# nrf9120 register map
Vendor: Nordic Semiconductor; Series: nrf91; File version: 1
CPU: CM33 r0p4, little endian, MPU, FPU, 3 interrupt priority bits, 69 interrupts
Registers are 32-bit, read-write, reset 0x0 unless marked. A register's access mark holds for its fields unless they carry their own. Offsets are from the block's base; [hi:lo] are bit positions; lines under a group give offsets from that group; {n}, {i} and the like mark numbered series; 'fields as' and 'values as' point back to an identical list.

## POWER_NS — Power control 0
Base 0x40005000; alternate view of CLOCK_NS
Same registers: POWER_S 0x50005000 (alternate view of CLOCK_S)
0x70 TASKS_PWMREQSTART wo — Request forcing PWM mode in external DC/DC voltage regulator. (Drives FPWM_DCDC pin high or low depending on a setting in UICR).
  [0] TASKS_PWMREQSTART
    1=Trigger task
0x74 TASKS_PWMREQSTOP wo — Stop requesting forcing PWM mode in external DC/DC voltage regulator
  [0] TASKS_PWMREQSTOP
    1=Trigger task
0x78 TASKS_CONSTLAT wo — Enable constant latency mode.
  [0] TASKS_CONSTLAT
    1=Trigger task
0x7C TASKS_LOWPWR wo — Enable low power mode (variable latency)
  [0] TASKS_LOWPWR
    1=Trigger task
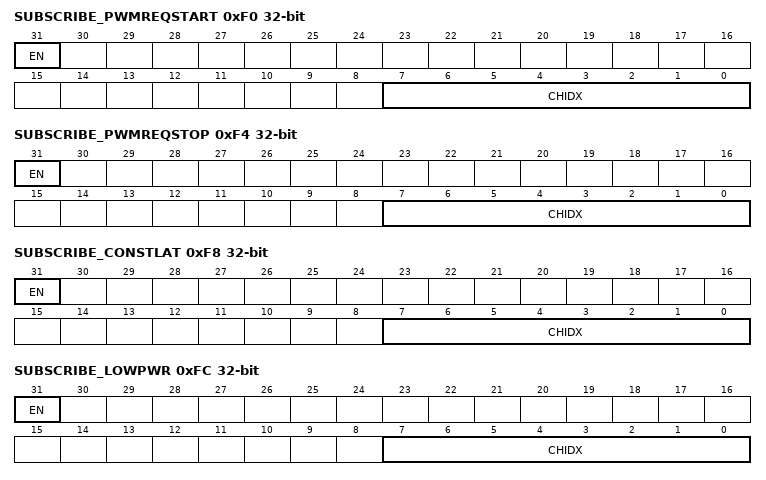
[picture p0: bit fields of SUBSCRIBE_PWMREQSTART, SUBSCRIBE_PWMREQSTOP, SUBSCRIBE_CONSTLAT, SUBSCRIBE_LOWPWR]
0xF0 SUBSCRIBE_PWMREQSTART — Subscribe configuration for task PWMREQSTART
  [31] EN
    0=Disabled (Disable subscription); 1=Enabled (Enable subscription)
  [7:0] CHIDX — DPPI channel that task PWMREQSTART will subscribe to
0xF4 SUBSCRIBE_PWMREQSTOP — Subscribe configuration for task PWMREQSTOP
  [31] EN
    values as SUBSCRIBE_PWMREQSTART.EN
  [7:0] CHIDX — DPPI channel that task PWMREQSTOP will subscribe to
0xF8 SUBSCRIBE_CONSTLAT — Subscribe configuration for task CONSTLAT
  [31] EN
    values as SUBSCRIBE_PWMREQSTART.EN
  [7:0] CHIDX — DPPI channel that task CONSTLAT will subscribe to
0xFC SUBSCRIBE_LOWPWR — Subscribe configuration for task LOWPWR
  [31] EN
    values as SUBSCRIBE_PWMREQSTART.EN
  [7:0] CHIDX — DPPI channel that task LOWPWR will subscribe to
0x108 EVENTS_POFWARN — Power failure warning
  [0] EVENTS_POFWARN
    0=NotGenerated (Event not generated); 1=Generated (Event generated)
0x114 EVENTS_SLEEPENTER — CPU entered WFI/WFE sleep
  [0] EVENTS_SLEEPENTER
    values as EVENTS_POFWARN.EVENTS_POFWARN
0x118 EVENTS_SLEEPEXIT — CPU exited WFI/WFE sleep
  [0] EVENTS_SLEEPEXIT
    values as EVENTS_POFWARN.EVENTS_POFWARN
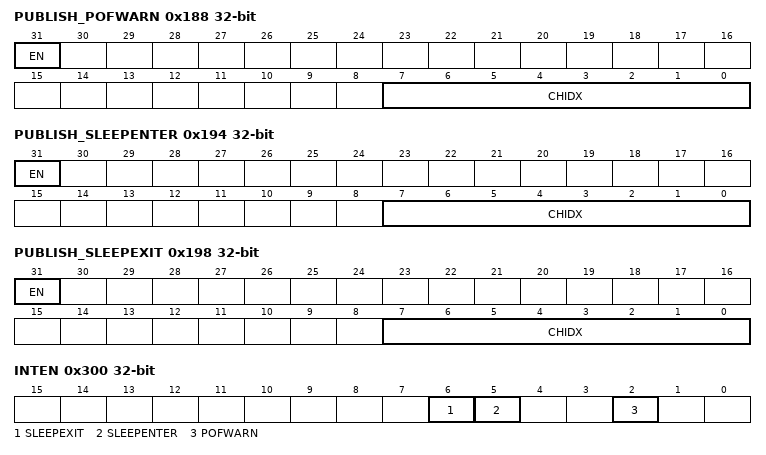
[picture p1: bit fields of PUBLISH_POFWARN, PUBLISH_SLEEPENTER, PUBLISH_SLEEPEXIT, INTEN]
0x188 PUBLISH_POFWARN — Publish configuration for event POFWARN
  [31] EN
    0=Disabled (Disable publishing); 1=Enabled (Enable publishing)
  [7:0] CHIDX — DPPI channel that event POFWARN will publish to
0x194 PUBLISH_SLEEPENTER — Publish configuration for event SLEEPENTER
  [31] EN
    values as PUBLISH_POFWARN.EN
  [7:0] CHIDX — DPPI channel that event SLEEPENTER will publish to
0x198 PUBLISH_SLEEPEXIT — Publish configuration for event SLEEPEXIT
  [31] EN
    values as PUBLISH_POFWARN.EN
  [7:0] CHIDX — DPPI channel that event SLEEPEXIT will publish to
0x300 INTEN — Enable or disable interrupt
  [all] fields
    0=Disabled; 1=Enabled
  [6] SLEEPEXIT — Enable or disable interrupt for event SLEEPEXIT
  [5] SLEEPENTER — Enable or disable interrupt for event SLEEPENTER
  [2] POFWARN — Enable or disable interrupt for event POFWARN
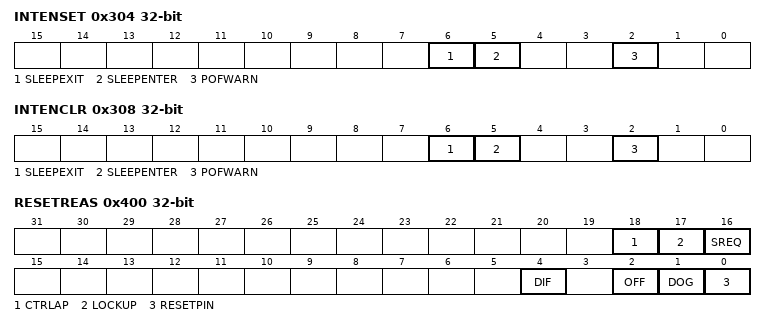
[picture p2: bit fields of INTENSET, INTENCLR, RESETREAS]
0x304 INTENSET — Enable interrupt
  [all] fields
    on read: 0=Disabled (Read: Disabled); 1=Enabled (Read: Enabled) | on write: 1=Set (Enable)
  [6] SLEEPEXIT — Write '1' to enable interrupt for event SLEEPEXIT
  [5] SLEEPENTER — Write '1' to enable interrupt for event SLEEPENTER
  [2] POFWARN — Write '1' to enable interrupt for event POFWARN
0x308 INTENCLR — Disable interrupt
  [all] fields
    on read: 0=Disabled (Read: Disabled); 1=Enabled (Read: Enabled) | on write: 1=Clear (Disable)
  [6] SLEEPEXIT — Write '1' to disable interrupt for event SLEEPEXIT
  [5] SLEEPENTER — Write '1' to disable interrupt for event SLEEPENTER
  [2] POFWARN — Write '1' to disable interrupt for event POFWARN
0x400 RESETREAS — Reset reason
  [all] fields
    0=NotDetected; 1=Detected
  [18] CTRLAP — Reset triggered through CTRL-AP
  [17] LOCKUP — Reset from CPU lock-up detected
  [16] SREQ — Reset from AIRCR.SYSRESETREQ detected
  [4] DIF — Reset due to wakeup from System OFF mode, when wakeup is triggered by entering debug interface mode
  [2] OFF — Reset due to wakeup from System OFF mode, when wakeup is triggered by DETECT signal from GPIO
  [1] DOG — Reset from global watchdog detected
  [0] RESETPIN — Reset from pin reset detected
0x440 POWERSTATUS ro — Modem domain power status
  [0] LTEMODEM — LTE modem domain status
    0=OFF (LTE modem domain is powered off); 1=ON (LTE modem domain is powered on)
{0x51C+4i} GPREGRET[{i}] (i=0..1) — Description collection: General purpose retention register
  [7:0] GPREGRET — General purpose retention register
0x610 LTEMODEM group
  0x00 STARTN reset 0x1 — Start LTE modem
    [0] STARTN
      0=Start LTE modem; 1=Hold LTE modem disabled
  0x04 FORCEOFF — Force off LTE modem
    [0] FORCEOFF
      0=Release force off; 1=Hold force off active

## Notices in the file
Copyright (c) 2010 - 2024, Nordic Semiconductor ASA
All rights reserved.
Redistribution and use in source and binary forms, with or without modification,
are permitted provided that the following conditions are met:
1. Redistributions of source code must retain the above copyright notice, this
list of conditions and the following disclaimer.
2. Redistributions in binary form, except as embedded into a Nordic
Semiconductor ASA integrated circuit in a product or a software update for
such product, must reproduce the above copyright notice, this list of
conditions and the following disclaimer in the documentation and/or other
materials provided with the distribution.
3. Neither the name of Nordic Semiconductor ASA nor the names of its
contributors may be used to endorse or promote products derived from this
software without specific prior written permission.
4. This software, with or without modification, must only be used with a
Nordic Semiconductor ASA integrated circuit.
5. Any software provided in binary form under this license must not be reverse
engineered, decompiled, modified and/or disassembled.
THIS SOFTWARE IS PROVIDED BY NORDIC SEMICONDUCTOR ASA "AS IS" AND ANY EXPRESS
OR IMPLIED WARRANTIES, INCLUDING, BUT NOT LIMITED TO, THE IMPLIED WARRANTIES
OF MERCHANTABILITY, NONINFRINGEMENT, AND FITNESS FOR A PARTICULAR PURPOSE ARE
DISCLAIMED. IN NO EVENT SHALL NORDIC SEMICONDUCTOR ASA OR CONTRIBUTORS BE
LIABLE FOR ANY DIRECT, INDIRECT, INCIDENTAL, SPECIAL, EXEMPLARY, OR
CONSEQUENTIAL DAMAGES (INCLUDING, BUT NOT LIMITED TO, PROCUREMENT OF SUBSTITUTE
GOODS OR SERVICES; LOSS OF USE, DATA, OR PROFITS; OR BUSINESS INTERRUPTION)
HOWEVER CAUSED AND ON ANY THEORY OF LIABILITY, WHETHER IN CONTRACT, STRICT
LIABILITY, OR TORT (INCLUDING NEGLIGENCE OR OTHERWISE) ARISING IN ANY WAY OUT
OF THE USE OF THIS SOFTWARE, EVEN IF ADVISED OF THE POSSIBILITY OF SUCH DAMAGE.
